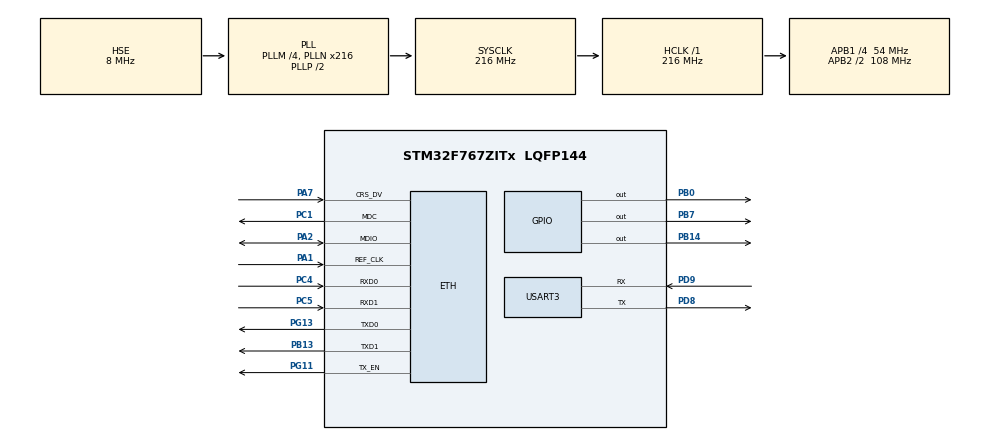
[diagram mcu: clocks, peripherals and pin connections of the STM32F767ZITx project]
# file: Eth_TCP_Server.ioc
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CORTEX_M7.CPU_DCache=Enabled
CORTEX_M7.CPU_ICache=Enabled
CORTEX_M7.PREFETCH_ENABLE=1
ETH.MediaInterface=ETH_MEDIA_INTERFACE_RMII
ETH.PhyAddress=0
LWIP.GATEWAY_ADDRESS=192.168.178.001
LWIP.IP_ADDRESS=192.168.178.132
LWIP.LWIP_DHCP=0
LWIP.MEM_SIZE=10*1024
LWIP.NETMASK_ADDRESS=255.255.255.000
LWIP.Version=v2.1.2_Cube
Mcu.Family=STM32F7
Mcu.Name=STM32F767ZITx
Mcu.Package=LQFP144
NVIC.ETH_IRQn=true\:0\:0\:false\:false\:true\:true\:true\:true
NVIC.PriorityGroup=NVIC_PRIORITYGROUP_4
PA1.Mode=RMII
PA1.Signal=ETH_REF_CLK
PA2.Mode=RMII
PA2.Signal=ETH_MDIO
PA7.Mode=RMII
PA7.Signal=ETH_CRS_DV
PB0.Signal=GPIO_Output
PB13.Mode=RMII
PB13.Signal=ETH_TXD1
PB14.Signal=GPIO_Output
PB7.Signal=GPIO_Output
PC1.Mode=RMII
PC1.Signal=ETH_MDC
PC4.Mode=RMII
PC4.Signal=ETH_RXD0
PC5.Mode=RMII
PC5.Signal=ETH_RXD1
PD8.Mode=Asynchronous
PD8.Signal=USART3_TX
PD9.Mode=Asynchronous
PD9.Signal=USART3_RX
PG11.Mode=RMII
PG11.Signal=ETH_TX_EN
PG13.Mode=RMII
PG13.Signal=ETH_TXD0
PH0/OSC_IN.Mode=HSE-External-Oscillator
PH0/OSC_IN.Signal=RCC_OSC_IN
PH1/OSC_OUT.Mode=HSE-External-Oscillator
PH1/OSC_OUT.Signal=RCC_OSC_OUT
ProjectManager.HeapSize=0x200
ProjectManager.StackSize=0x400
ProjectManager.TargetToolchain=STM32CubeIDE
RCC.AHBFreq_Value=216000000
RCC.APB1CLKDivider=RCC_HCLK_DIV4
RCC.APB1Freq_Value=54000000
RCC.APB1TimFreq_Value=108000000
RCC.APB2CLKDivider=RCC_HCLK_DIV2
RCC.APB2Freq_Value=108000000
RCC.APB2TimFreq_Value=216000000
RCC.CortexFreq_Value=216000000
RCC.HCLKFreq_Value=216000000
RCC.HSE_VALUE=8000000
RCC.HSI_VALUE=16000000
RCC.LSE_VALUE=32768
RCC.PLLM=4
RCC.PLLN=216
RCC.PLLSourceVirtual=RCC_PLLSOURCE_HSE
RCC.SYSCLKFreq_VALUE=216000000
RCC.SYSCLKSource=RCC_SYSCLKSOURCE_PLLCLK
RCC.USBFreq_Value=216000000
RCC.VCOOutputFreq_Value=432000000
USART3.VirtualMode-Asynchronous=VM_ASYNC
VP_LWIP_VS_Enabled.Mode=Enabled
board=custom

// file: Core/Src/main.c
/* USER CODE BEGIN Header */
/**
  ******************************************************************************
  * @file           : main.c
  * @brief          : Main program body
  ******************************************************************************
  * @author			: Jabed-Akhtar (GitHub)
  * @date			: ---
  ******************************************************************************
  * @attention
  *		-> ---
  *
  *	Imp note:
  *		- ---
  *
  * Project-Related infos:
  * 	- a source used within this project: https://controllerstech.com/stm32-ethernet-4-tcp-server/
  * 	- evicences/pics can be found at location: '<project-main-folder>/zz_docs/***.***'
  *
  *	Description:
  *		- This project is very basic. Only connection through ping (ICMP)
  *		- MCU-Board IP Address: 192.168.000.111
  *
  ******************************************************************************
  */
/* USER CODE END Header */
#include "main.h"
#include "lwip.h"

/* USER CODE BEGIN Includes */
#include "tcpServerRAW.h"
/* USER CODE END Includes */

UART_HandleTypeDef huart3;

/* USER CODE BEGIN PV */
extern struct netif gnetif;
/* USER CODE END PV */

void SystemClock_Config(void);
static void MX_GPIO_Init(void);
static void MX_USART3_UART_Init(void);

int main(void)
{

  /* Enable I-Cache---------------------------------------------------------*/
  SCB_EnableICache();

  /* Enable D-Cache---------------------------------------------------------*/
  SCB_EnableDCache();

  /* MCU Configuration--------------------------------------------------------*/

  /* Reset of all peripherals, Initializes the Flash interface and the Systick. */
  HAL_Init();

  /* Configure the system clock */
  SystemClock_Config();

  /* Initialize all configured peripherals */
  MX_GPIO_Init();
  MX_USART3_UART_Init();
  MX_LWIP_Init();
  /* USER CODE BEGIN 2 */

  // Initialize the TCP Server
  tcp_server_init();

  /* USER CODE END 2 */

  /* Infinite loop */
  while (1)
  {

    /* USER CODE BEGIN 3 */
	  ethernetif_input(&gnetif);
	  sys_check_timeouts();
  }
  /* USER CODE END 3 */
}

void SystemClock_Config(void)
{
  RCC_OscInitTypeDef RCC_OscInitStruct = {0};
  RCC_ClkInitTypeDef RCC_ClkInitStruct = {0};

  /** Configure the main internal regulator output voltage
  */
  __HAL_RCC_PWR_CLK_ENABLE();
  __HAL_PWR_VOLTAGESCALING_CONFIG(PWR_REGULATOR_VOLTAGE_SCALE1);

  /** Initializes the RCC Oscillators according to the specified parameters
  * in the RCC_OscInitTypeDef structure.
  */
  RCC_OscInitStruct.OscillatorType = RCC_OSCILLATORTYPE_HSE;
  RCC_OscInitStruct.HSEState = RCC_HSE_ON;
  RCC_OscInitStruct.PLL.PLLState = RCC_PLL_ON;
  RCC_OscInitStruct.PLL.PLLSource = RCC_PLLSOURCE_HSE;
  RCC_OscInitStruct.PLL.PLLM = 4;
  RCC_OscInitStruct.PLL.PLLN = 216;
  RCC_OscInitStruct.PLL.PLLP = RCC_PLLP_DIV2;
  RCC_OscInitStruct.PLL.PLLQ = 2;
  RCC_OscInitStruct.PLL.PLLR = 2;
  if (HAL_RCC_OscConfig(&RCC_OscInitStruct) != HAL_OK)
  {
    Error_Handler();
  }

  /** Activate the Over-Drive mode
  */
  if (HAL_PWREx_EnableOverDrive() != HAL_OK)
  {
    Error_Handler();
  }

  /** Initializes the CPU, AHB and APB buses clocks
  */
  RCC_ClkInitStruct.ClockType = RCC_CLOCKTYPE_HCLK|RCC_CLOCKTYPE_SYSCLK
                              |RCC_CLOCKTYPE_PCLK1|RCC_CLOCKTYPE_PCLK2;
  RCC_ClkInitStruct.SYSCLKSource = RCC_SYSCLKSOURCE_PLLCLK;
  RCC_ClkInitStruct.AHBCLKDivider = RCC_SYSCLK_DIV1;
  RCC_ClkInitStruct.APB1CLKDivider = RCC_HCLK_DIV4;
  RCC_ClkInitStruct.APB2CLKDivider = RCC_HCLK_DIV2;

  if (HAL_RCC_ClockConfig(&RCC_ClkInitStruct, FLASH_LATENCY_7) != HAL_OK)
  {
    Error_Handler();
  }
}

static void MX_USART3_UART_Init(void)
{

  huart3.Instance = USART3;
  huart3.Init.BaudRate = 115200;
  huart3.Init.WordLength = UART_WORDLENGTH_8B;
  huart3.Init.StopBits = UART_STOPBITS_1;
  huart3.Init.Parity = UART_PARITY_NONE;
  huart3.Init.Mode = UART_MODE_TX_RX;
  huart3.Init.HwFlowCtl = UART_HWCONTROL_NONE;
  huart3.Init.OverSampling = UART_OVERSAMPLING_16;
  huart3.Init.OneBitSampling = UART_ONE_BIT_SAMPLE_DISABLE;
  huart3.AdvancedInit.AdvFeatureInit = UART_ADVFEATURE_NO_INIT;
  if (HAL_UART_Init(&huart3) != HAL_OK)
  {
    Error_Handler();
  }

}

static void MX_GPIO_Init(void)
{
  GPIO_InitTypeDef GPIO_InitStruct = {0};

  /* GPIO Ports Clock Enable */
  __HAL_RCC_GPIOH_CLK_ENABLE();
  __HAL_RCC_GPIOC_CLK_ENABLE();
  __HAL_RCC_GPIOA_CLK_ENABLE();
  __HAL_RCC_GPIOB_CLK_ENABLE();
  __HAL_RCC_GPIOD_CLK_ENABLE();
  __HAL_RCC_GPIOG_CLK_ENABLE();

  /*Configure GPIO pin Output Level */
  HAL_GPIO_WritePin(GPIOB, GPIO_PIN_0|GPIO_PIN_14|GPIO_PIN_7, GPIO_PIN_RESET);

  /*Configure GPIO pins : PB0 PB14 PB7 */
  GPIO_InitStruct.Pin = GPIO_PIN_0|GPIO_PIN_14|GPIO_PIN_7;
  GPIO_InitStruct.Mode = GPIO_MODE_OUTPUT_PP;
  GPIO_InitStruct.Pull = GPIO_NOPULL;
  GPIO_InitStruct.Speed = GPIO_SPEED_FREQ_LOW;
  HAL_GPIO_Init(GPIOB, &GPIO_InitStruct);

}

void Error_Handler(void)
{
  __disable_irq();
  while (1)
  {
  }
}
